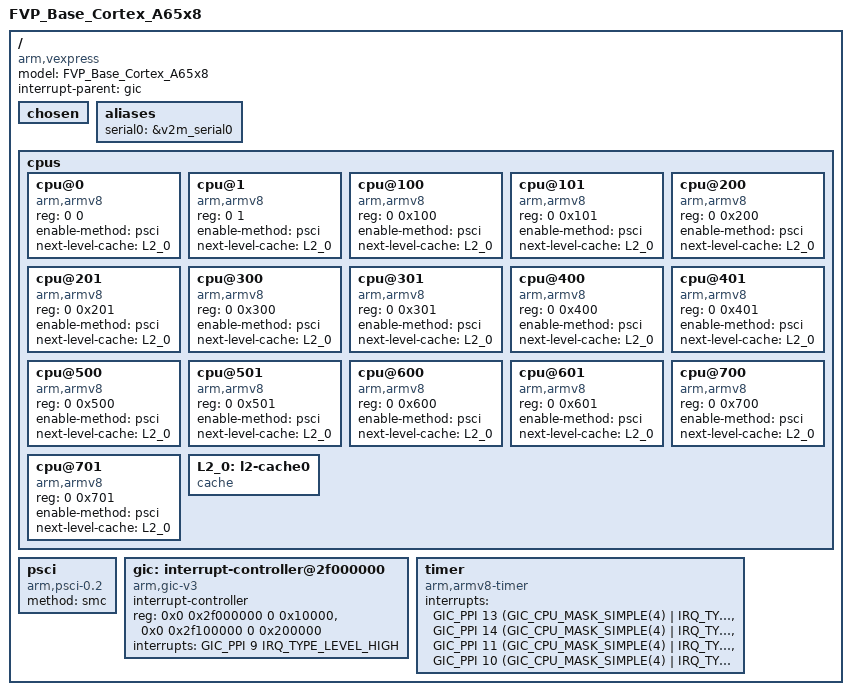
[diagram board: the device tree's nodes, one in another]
/*
 * SPDX-License-Identifier: Apache-2.0
 * Copyright (c) 2019 KapaXL (kapa.xl@outlook.com)
 *
 * MultiThreading Supports:
 *
 * FVP_Base_Cortex_A65, FVP_Base_Cortex_A65AE
 * FVP_Base_Neoverse_E1
 *
 * (Each core has 2 threads, total 8x2=16 threads)
 */

/dts-v1/;

#include "memory.dtsi"
#include "vexpress_ca65m.dtsi"

/ {
	model = "FVP_Base_Cortex_A65x8";
	compatible = "arm,vexpress";
	interrupt-parent = <&gic>;
	#address-cells = <2>;
	#size-cells = <2>;

	chosen { };

	aliases {
		serial0 = &v2m_serial0;
	};

	cpus {
		#address-cells = <2>;
		#size-cells = <0>;

		cpu@0 {
			device_type = "cpu";
			compatible = "arm,armv8";
			reg = <0 0>;
			enable-method = "psci";
			next-level-cache = <&L2_0>;
		};
		cpu@1 {
			device_type = "cpu";
			compatible = "arm,armv8";
			reg = <0 1>;
			enable-method = "psci";
			next-level-cache = <&L2_0>;
		};

		cpu@100 {
			device_type = "cpu";
			compatible = "arm,armv8";
			reg = <0 0x100>;
			enable-method = "psci";
			next-level-cache = <&L2_0>;
		};
		cpu@101 {
			device_type = "cpu";
			compatible = "arm,armv8";
			reg = <0 0x101>;
			enable-method = "psci";
			next-level-cache = <&L2_0>;
		};

		cpu@200 {
			device_type = "cpu";
			compatible = "arm,armv8";
			reg = <0 0x200>;
			enable-method = "psci";
			next-level-cache = <&L2_0>;
		};
		cpu@201 {
			device_type = "cpu";
			compatible = "arm,armv8";
			reg = <0 0x201>;
			enable-method = "psci";
			next-level-cache = <&L2_0>;
		};

		cpu@300 {
			device_type = "cpu";
			compatible = "arm,armv8";
			reg = <0 0x300>;
			enable-method = "psci";
			next-level-cache = <&L2_0>;
		};
		cpu@301 {
			device_type = "cpu";
			compatible = "arm,armv8";
			reg = <0 0x301>;
			enable-method = "psci";
			next-level-cache = <&L2_0>;
		};

		cpu@400 {
			device_type = "cpu";
			compatible = "arm,armv8";
			reg = <0 0x400>;
			enable-method = "psci";
			next-level-cache = <&L2_0>;
		};
		cpu@401 {
			device_type = "cpu";
			compatible = "arm,armv8";
			reg = <0 0x401>;
			enable-method = "psci";
			next-level-cache = <&L2_0>;
		};

		cpu@500 {
			device_type = "cpu";
			compatible = "arm,armv8";
			reg = <0 0x500>;
			enable-method = "psci";
			next-level-cache = <&L2_0>;
		};
		cpu@501 {
			device_type = "cpu";
			compatible = "arm,armv8";
			reg = <0 0x501>;
			enable-method = "psci";
			next-level-cache = <&L2_0>;
		};

		cpu@600 {
			device_type = "cpu";
			compatible = "arm,armv8";
			reg = <0 0x600>;
			enable-method = "psci";
			next-level-cache = <&L2_0>;
		};
		cpu@601 {
			device_type = "cpu";
			compatible = "arm,armv8";
			reg = <0 0x601>;
			enable-method = "psci";
			next-level-cache = <&L2_0>;
		};

		cpu@700 {
			device_type = "cpu";
			compatible = "arm,armv8";
			reg = <0 0x700>;
			enable-method = "psci";
			next-level-cache = <&L2_0>;
		};
		cpu@701 {
			device_type = "cpu";
			compatible = "arm,armv8";
			reg = <0 0x701>;
			enable-method = "psci";
			next-level-cache = <&L2_0>;
		};

		L2_0: l2-cache0 {
			compatible = "cache";
		};
	};

	psci {
		compatible = "arm,psci-0.2";
		method = "smc";
	};

	gic: interrupt-controller@2f000000 {
		compatible = "arm,gic-v3";
		#interrupt-cells = <3>;
		#address-cells = <0>;
		interrupt-controller;
		reg = <0x0 0x2f000000 0 0x10000>,		// GICD
			  <0x0 0x2f100000 0 0x200000>;		// GICR
		interrupts = <GIC_PPI 9 IRQ_TYPE_LEVEL_HIGH>;
	};

	timer {
		compatible = "arm,armv8-timer";
		interrupts = <GIC_PPI 13 (GIC_CPU_MASK_SIMPLE(4) | IRQ_TYPE_LEVEL_LOW)>,
				 <GIC_PPI 14 (GIC_CPU_MASK_SIMPLE(4) | IRQ_TYPE_LEVEL_LOW)>,
				 <GIC_PPI 11 (GIC_CPU_MASK_SIMPLE(4) | IRQ_TYPE_LEVEL_LOW)>,
				 <GIC_PPI 10 (GIC_CPU_MASK_SIMPLE(4) | IRQ_TYPE_LEVEL_LOW)>;
	};
};
